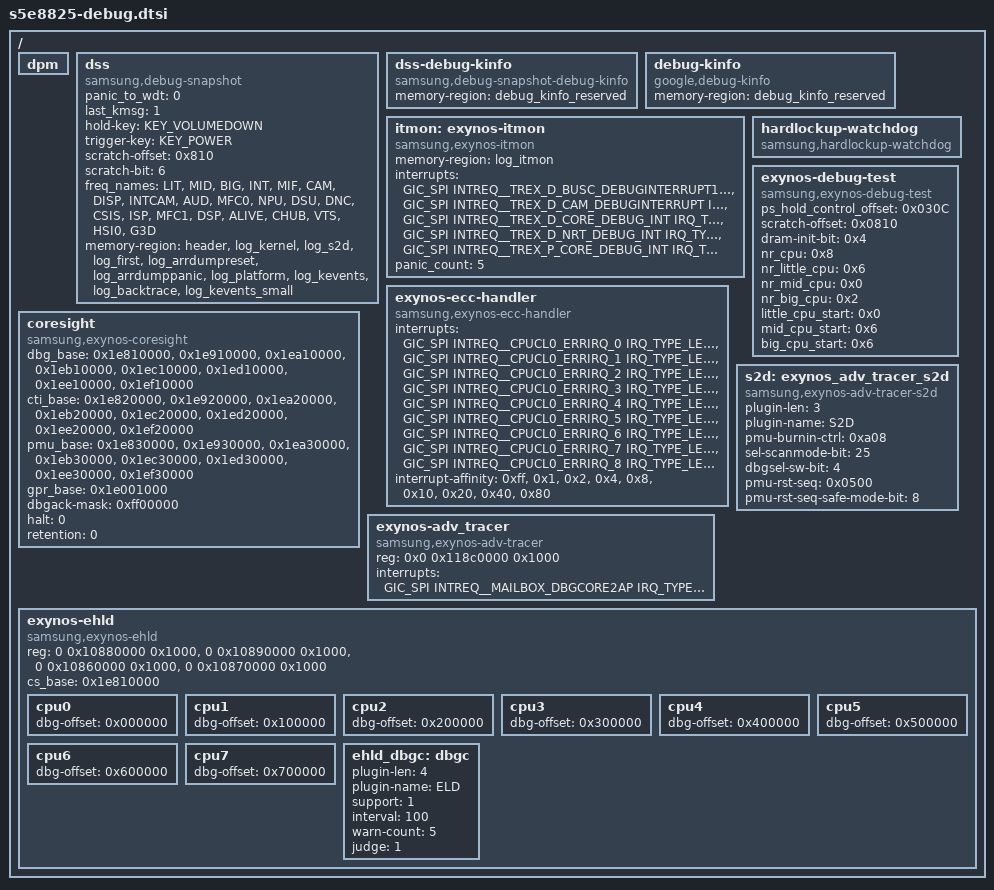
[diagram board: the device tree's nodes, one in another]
// SPDX-License-Identifier: GPL-2.0-only

#include <dt-bindings/interrupt-controller/s5e8825.h>
#include <dt-bindings/input/linux-event-codes.h>

/ {
	dpm: dpm {
	};

	dss: dss {
		compatible = "samsung,debug-snapshot";
		panic_to_wdt = <0>;
		last_kmsg = <1>;
		hold-key = <KEY_VOLUMEDOWN>;
		trigger-key = <KEY_POWER>;
		scratch-offset = <0x810>; /* SYSIP_DAT0 */
		scratch-bit = <6>;
		freq_names = "LIT", "MID", "BIG", "INT", "MIF", "CAM",
				"DISP", "INTCAM", "AUD", "MFC0", "NPU", "DSU",
				"DNC", "CSIS", "ISP", "MFC1", "DSP", "ALIVE",
				"CHUB", "VTS", "HSI0", "G3D";
		memory-region = <&header>, <&log_kernel>, <&log_s2d>,
				<&log_first>, <&log_arrdumpreset>,
				<&log_arrdumppanic>, <&log_platform>,
				<&log_kevents>, <&log_backtrace>, <&log_kevents_small>;
	};

	dss-debug-kinfo {
		compatible = "samsung,debug-snapshot-debug-kinfo";
		memory-region = <&debug_kinfo_reserved>;
	};

	debug-kinfo {
		compatible = "google,debug-kinfo";
		memory-region = <&debug_kinfo_reserved>;
	};

	itmon: exynos-itmon {
		compatible = "samsung,exynos-itmon";
		memory-region = <&log_itmon>;
		interrupts =	<GIC_SPI INTREQ__TREX_D_BUSC_DEBUGINTERRUPT1
					IRQ_TYPE_LEVEL_HIGH>, /* BUS_DATA0 */
				<GIC_SPI INTREQ__TREX_D_CAM_DEBUGINTERRUPT
					IRQ_TYPE_LEVEL_HIGH>, /* BUS_DATA1 */
				<GIC_SPI INTREQ__TREX_D_CORE_DEBUG_INT
					IRQ_TYPE_LEVEL_HIGH>, /* BUS_DATA2 */
				<GIC_SPI INTREQ__TREX_D_NRT_DEBUG_INT
					IRQ_TYPE_LEVEL_HIGH>, /* BUS_DATA3 */
				<GIC_SPI INTREQ__TREX_P_CORE_DEBUG_INT
					IRQ_TYPE_LEVEL_HIGH>; /* BUS_PERI0 */
		panic_count = <5>;
	};

	hardlockup-watchdog {
		compatible = "samsung,hardlockup-watchdog";
	};

	exynos-debug-test {
		compatible = "samsung,exynos-debug-test";
		ps_hold_control_offset = <0x030C>;
		scratch-offset = <0x0810>; /* SYSIP_DAT0 */
		dram-init-bit = <0x4>;
		nr_cpu = <0x8>;
		nr_little_cpu = <0x6>;
		nr_mid_cpu = <0x0>;
		nr_big_cpu = <0x2>;
		little_cpu_start = <0x0>;
		mid_cpu_start = <0x6>;
		big_cpu_start = <0x6>;
	};

	exynos-ecc-handler {
		compatible = "samsung,exynos-ecc-handler";
		interrupts = <GIC_SPI INTREQ__CPUCL0_ERRIRQ_0 IRQ_TYPE_LEVEL_HIGH>,
			<GIC_SPI INTREQ__CPUCL0_ERRIRQ_1 IRQ_TYPE_LEVEL_HIGH>,
			<GIC_SPI INTREQ__CPUCL0_ERRIRQ_2 IRQ_TYPE_LEVEL_HIGH>,
			<GIC_SPI INTREQ__CPUCL0_ERRIRQ_3 IRQ_TYPE_LEVEL_HIGH>,
			<GIC_SPI INTREQ__CPUCL0_ERRIRQ_4 IRQ_TYPE_LEVEL_HIGH>,
			<GIC_SPI INTREQ__CPUCL0_ERRIRQ_5 IRQ_TYPE_LEVEL_HIGH>,
			<GIC_SPI INTREQ__CPUCL0_ERRIRQ_6 IRQ_TYPE_LEVEL_HIGH>,
			<GIC_SPI INTREQ__CPUCL0_ERRIRQ_7 IRQ_TYPE_LEVEL_HIGH>,
			<GIC_SPI INTREQ__CPUCL0_ERRIRQ_8 IRQ_TYPE_LEVEL_HIGH>;
		interrupt-names = "Uncorrectable errors Cache(L3) tag RAMs or SCU snoop filter RAMs",
			"Core0, Uncorrectable errors in the L1 tag or dirty or L2 tag RAMs",
			"Core1, Uncorrectable errors in the L1 tag or dirty or L2 tag RAMs",
			"Core2, Uncorrectable errors in the L1 tag or dirty or L2 tag RAMs",
			"Core3, Uncorrectable errors in the L1 tag or dirty or L2 tag RAMs",
			"Core4, Uncorrectable errors in the L1 tag or dirty or L2 tag RAMs",
			"Core5, Uncorrectable errors in the L1 tag or dirty or L2 tag RAMs",
			"Core6, Uncorrectable errors in the L1 tag or dirty or L2 tag RAMs",
			"Core7, Uncorrectable errors in the L1 tag or dirty or L2 tag RAMs";
		interrupt-affinity = <0xff>, <0x1>, <0x2>, <0x4>, <0x8>,
				<0x10>, <0x20>, <0x40>, <0x80>;
	};

	coresight {
		compatible = "samsung,exynos-coresight";
		dbg_base = <0x1e810000>, <0x1e910000>, <0x1ea10000>, <0x1eb10000>,
			   <0x1ec10000>, <0x1ed10000>, <0x1ee10000>, <0x1ef10000>;
		cti_base = <0x1e820000>, <0x1e920000>, <0x1ea20000>, <0x1eb20000>,
			   <0x1ec20000>, <0x1ed20000>, <0x1ee20000>, <0x1ef20000>;
		pmu_base = <0x1e830000>, <0x1e930000>, <0x1ea30000>, <0x1eb30000>,
			   <0x1ec30000>, <0x1ed30000>, <0x1ee30000>, <0x1ef30000>;
		gpr_base = <0x1e001000>;
		dbgack-mask = <0xff00000>;
		halt = <0>;
		retention = <0>;
	};

	exynos-adv_tracer {
		compatible = "samsung,exynos-adv-tracer";
		reg = <0x0 0x118c0000 0x1000>;
		reg-names = "mailbox";
		interrupts = <GIC_SPI INTREQ__MAILBOX_DBGCORE2AP IRQ_TYPE_LEVEL_HIGH>;
		status = "ok";
	};

	s2d: exynos_adv_tracer_s2d {
		compatible = "samsung,exynos-adv-tracer-s2d";
		plugin-len = <3>;
		plugin-name = "S2D";
		pmu-burnin-ctrl = <0xa08>;
		sel-scanmode-bit = <25>;
		dbgsel-sw-bit = <4>;
		pmu-rst-seq = <0x0500>;
		pmu-rst-seq-safe-mode-bit = <8>;
		status = "ok";
	};

	exynos-ehld {
		compatible = "samsung,exynos-ehld";
		reg = <0 0x10880000 0x1000>,
			<0 0x10890000 0x1000>,
			<0 0x10860000 0x1000>,
			<0 0x10870000 0x1000>;
		cs_base = <0x1e810000>;
		cpu0 {
			dbg-offset = <0x000000>;
		};
		cpu1 {
			dbg-offset = <0x100000>;
		};
		cpu2 {
			dbg-offset = <0x200000>;
		};
		cpu3 {
			dbg-offset = <0x300000>;
		};
		cpu4 {
			dbg-offset = <0x400000>;
		};
		cpu5 {
			dbg-offset = <0x500000>;
		};
		cpu6 {
			dbg-offset = <0x600000>;
		};
		cpu7 {
			dbg-offset = <0x700000>;
		};

		ehld_dbgc: dbgc {
			/* IPC */
			plugin-len = <4>;
			plugin-name = "ELD";
			support = <1>;
			interval = <100>;
			warn-count = <5>;
			judge = <1>;
		};
	};
};
